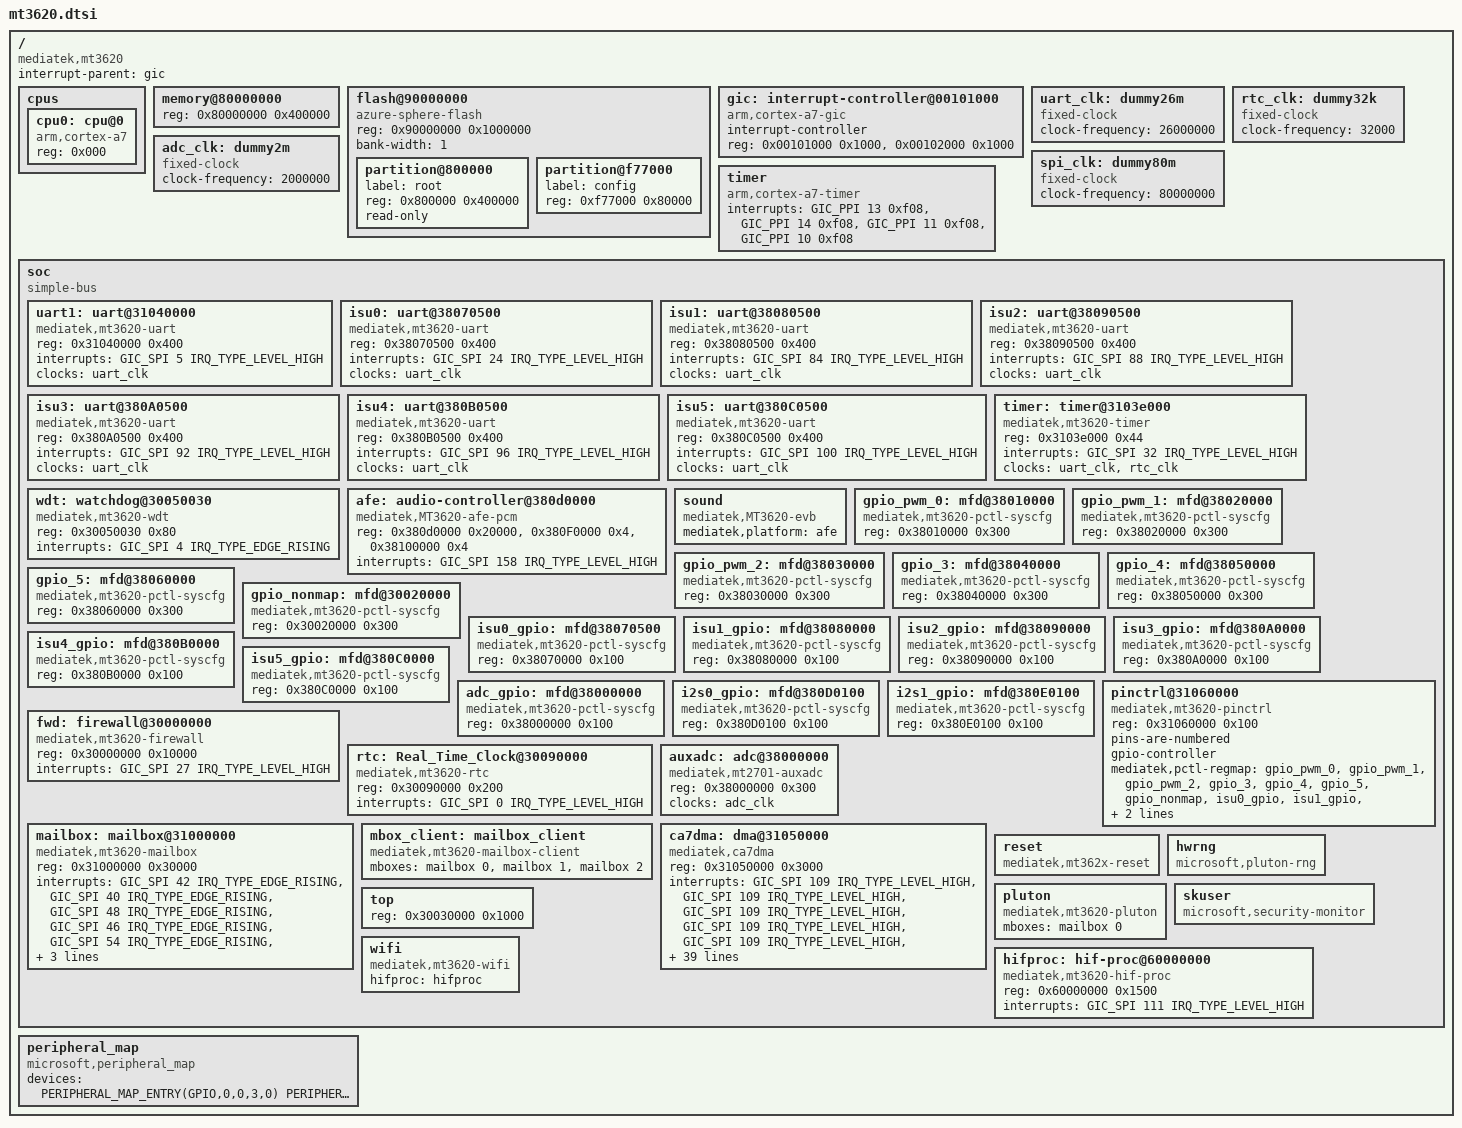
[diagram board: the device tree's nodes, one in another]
// SPDX-License-Identifier: GPL-2.0
/*
 * MT3620 SoC
 *
 * Copyright (c) 2018 Microsoft Corporation. All rights reserved.
 *
 * This program is free software; you can redistribute it and/or modify it
 * under the terms and conditions of the GNU General Public License,
 * version 2, as published by the Free Software Foundation.
 *
 * This program is distributed in the hope it will be useful, but WITHOUT
 * ANY WARRANTY; without even the implied warranty of MERCHANTABILITY or
 * FITNESS FOR A PARTICULAR PURPOSE.  See the GNU General Public License for
 * more details.
 *
 * You should have received a copy of the GNU General Public License along with
 * this program; if not, write to the Free Software Foundation, Inc., 59 Temple
 * Place - Suite 330, Boston, MA 02111-1307 USA.
 *
 */

#include <dt-bindings/interrupt-controller/irq.h>
#include <dt-bindings/interrupt-controller/arm-gic.h>
#include "mt3620-peripherals.dtsi"

/ {
	compatible = "mediatek,mt3620";
	interrupt-parent = <&gic>;

	//
	// We only need one 32-bit value each to represent physical addresses and
	// sizes.  This means that 'reg' values will tend to take the form:
	//
	//     <[addr] [size]>
	//

	#address-cells = <1>;
	#size-cells = <1>;

	//
	// We use 3 values to represent interrupts; from gic.txt:
	//   * 1st cell: 0 for SPI interrupts, 1 for PPI interrupts
	//   * 2nd cell: interrupt number (SPI: [0-987], PPI: [0-15])
	//   * 3rd cell: flags
	//     - bits[3:0]: trigger type / level flags
	//       + 1 = low-to-high edge triggered
	//       + 2 = high-to-low edge triggered (invalid for SPIs)
	//       + 4 = active high level-sensitive
	//       + 8 = active low level-sensitive (invalid for SPIs)
	//     - bits[15:8] PPI interrupt cpu mask; only valid for PPI interrupts
	//

	//
	// Define the CPU.
	//
	// ref: Documentation/devicetree/bindings/arm/cpus.txt
	//

	cpus {
		#address-cells = <1>;
		#size-cells = <0>;

		cpu0: cpu@0 {
			device_type = "cpu";
			compatible = "arm,cortex-a7";

			//
			// Register must match the CPU MPIDR[23:0] register bits.
			//

			reg = <0x000>;
		};
	};

	//
	// Define the A7's SRAMs.

	memory@80000000 {
		device_type = "memory";
		reg = <0x80000000 0x400000>;
	};

	//
	// We define a flash device to cover the XIP mapping of flash into the
	// physical address space.
	//
	// We mark the device as being "mtd-rom" so that it's managed by a read-only
	// MTD device that directly reads from physical memory.
	//
	// ref: Documentation/devicetree/bindings/mtd/mtd-physmap.txt
	//

	flash@90000000 {
		compatible = "azure-sphere-flash", "mtd-rom";
		reg = <0x90000000 0x1000000>;

		//
		// NOTE: We need to specify "bank-width" but it's not clear that
		// it has much meaning here.
		//

		bank-width = <1>;

		//
		// We define the partition structure here; note that this
		// will be overwritten by our NW loader based on the
		// partition table.
		//
		// ref: Documentation/devicetree/bindings/mtd/partition.txt
		//

		partition@800000 {
		    label = "root";
		    reg = <0x800000 0x400000>; /* 8 MiB - 12 MiB */
		    read-only;
		};

		partition@f77000 {
		    label = "config";
		    reg = <0xf77000 0x80000>;
		};
	};

	//
	// We have a GICv2 in our standard MPCore peripherals.
	//
	// ref: Documentation/devicetree/bindings/arm/gic.txt
	//

	gic: interrupt-controller@00101000 {
		compatible = "arm,cortex-a7-gic";
		#interrupt-cells = <3>;
		#address-cells = <0>;
		interrupt-controller;

		//
		// We need to specify the base physical addresses and sizes of the
		// GIC registers:
		//
		//   * Region 0: GIC distributor register base and size
		//   * Region 1: GIC CPU interface register base and size
		//
		// For ARM cores with virtualization extensions, additional registers
		// must be specified:
		//
		//   * Region 2: GIC virtual interface control register base and size
		//   * Region 3: GIC virtual CPU interface register base and size
		//
		// If present, the VGIC maintenance interrupt is specified as an
		// interrupt source here.
		//

		reg = <0x00101000 0x1000>,
		      <0x00102000 0x1000>;
	};

	//
	// The UART clock is based on a fixed, 26 MHz clock source.
	//
	// ref: Documentation/devicetree/bindings/clock/fixed-clock.txt
	//

	uart_clk: dummy26m {
		compatible = "fixed-clock";
		clock-frequency = <26000000>;
		#clock-cells = <0>;
	};

	rtc_clk: dummy32k {
		compatible = "fixed-clock";
		clock-frequency = <32000>;
		#clock-cells = <0>;
	};

	adc_clk: dummy2m {
		compatible = "fixed-clock";
		clock-frequency = <2000000>;
		#clock-cells = <0>;
	};

	// SPIM clock: 
	// selected by rg_spim_clk_div_sel; pluton-runtime
	// programs this this to 80MHz.

	spi_clk: dummy80m {
		compatible = "fixed-clock";
		clock-frequency = <80000000>;
		#clock-cells = <0>;
	};


	//
	// Include the ARM architectural timer.
	//
	// ref: Documentation/devicetree/bindings/arm/arch_timer.txt
	//

	timer {
		compatible = "arm,cortex-a7-timer",
			     "arm,armv7-timer";

		#interrupt-cells = <3>;

		interrupts = <GIC_PPI 13 0xf08>,
			     <GIC_PPI 14 0xf08>,
			     <GIC_PPI 11 0xf08>,
			     <GIC_PPI 10 0xf08>;
	};

	//
	// Define a simple bus that doesn't require a software driver.
	//
	// ref: Documentation/devicetree/bindings/arm/simple-pm-bus.txt
	//

	soc: soc {
		// 32-bit space
		#address-cells = <1>;
		#size-cells = <1>;

		compatible = "simple-bus";

		//
		// Indicate that there's an identify mapping for addresses on this bus.
		//

		ranges;

		//
		// Define the CA7 UARTs
		// They aren't actually ns16550a devices, but are
		// close-ish.
		//
		// ref: Documentation/devicetree/bindings/serial/8250.txt
		//

		// Debug UART

		uart1: uart@31040000 {
			compatible = "mediatek,mt3620-uart";
			reg = <0x31040000 0x400>;
			interrupts = <GIC_SPI 5 IRQ_TYPE_LEVEL_HIGH>;
			clocks = <&uart_clk>;
		};

		// ISUs

		isu0: uart@38070500 {
			compatible = "mediatek,mt3620-uart";
			reg = <0x38070500 0x400>;
			interrupts = <GIC_SPI 24 IRQ_TYPE_LEVEL_HIGH>;
			clocks = <&uart_clk>;
		};

		isu1: uart@38080500 {
			compatible = "mediatek,mt3620-uart";
			reg = <0x38080500 0x400>;
			interrupts = <GIC_SPI 84 IRQ_TYPE_LEVEL_HIGH>;
			clocks = <&uart_clk>;
		};

		isu2: uart@38090500 {
			compatible = "mediatek,mt3620-uart";
			reg = <0x38090500 0x400>;
			interrupts = <GIC_SPI 88 IRQ_TYPE_LEVEL_HIGH>;
			clocks = <&uart_clk>;
		};

		isu3: uart@380A0500 {
			compatible = "mediatek,mt3620-uart";
			reg = <0x380A0500 0x400>;
			interrupts = <GIC_SPI 92 IRQ_TYPE_LEVEL_HIGH>;
			clocks = <&uart_clk>;
		};

		isu4: uart@380B0500 {
			compatible = "mediatek,mt3620-uart";
			reg = <0x380B0500 0x400>;
			interrupts = <GIC_SPI 96 IRQ_TYPE_LEVEL_HIGH>;
			clocks = <&uart_clk>;
		};

		isu5: uart@380C0500 {
			compatible = "mediatek,mt3620-uart";
			reg = <0x380C0500 0x400>;
			interrupts = <GIC_SPI 100 IRQ_TYPE_LEVEL_HIGH>;
			clocks = <&uart_clk>;
		};

		timer: timer@3103e000 {
				compatible = "mediatek,mt3620-timer";
				reg = <0x3103e000 0x44>;
				interrupts = <GIC_SPI 32 IRQ_TYPE_LEVEL_HIGH>;
				clocks = <&uart_clk>, <&rtc_clk>;
				clock-names = "system-clk", "rtc-clk";
		};

		//
		// Define the A7's watchdog timer.
		//

		wdt: watchdog@30050030 {
				compatible = "mediatek,mt3620-wdt";
				reg = <0x30050030 0x80>;
				interrupts = <GIC_SPI 4 IRQ_TYPE_EDGE_RISING>;
		};

		// TODO: various peripherals that MTK defined here...

		afe: audio-controller@380d0000 {
			compatible = "mediatek,MT3620-afe-pcm";
			reg = <0x380d0000 0x20000>,
			      <0x380F0000 0x4>,
			      <0x38100000 0x4>;
			interrupts =<GIC_SPI 158 IRQ_TYPE_LEVEL_HIGH>;  //i2s0:158 i2s1:159
			//status = "disabled";
		};

		sound: sound {
			compatible = "mediatek,MT3620-evb";
			mediatek,platform = <&afe>;
			status = "okay";
		};

		gpio_pwm_0: mfd@38010000 {
			compatible = "mediatek,mt3620-pctl-syscfg", "syscon";
			reg = <0x38010000 0x300>;
		};

		gpio_pwm_1: mfd@38020000 {
			compatible = "mediatek,mt3620-pctl-syscfg", "syscon";
			reg = <0x38020000 0x300>;
		};

		gpio_pwm_2: mfd@38030000 {
			compatible = "mediatek,mt3620-pctl-syscfg", "syscon";
			reg = <0x38030000 0x300>;
		};

		gpio_3: mfd@38040000 {
			compatible = "mediatek,mt3620-pctl-syscfg", "syscon";
			reg = <0x38040000 0x300>;
		};

		gpio_4: mfd@38050000 {
			compatible = "mediatek,mt3620-pctl-syscfg", "syscon";
			reg = <0x38050000 0x300>;
		};

		gpio_5: mfd@38060000 {
			compatible = "mediatek,mt3620-pctl-syscfg", "syscon";
			reg = <0x38060000 0x300>;
		};

		gpio_nonmap: mfd@30020000 {
			compatible = "mediatek,mt3620-pctl-syscfg", "syscon";
			reg = <0x30020000 0x300>;
		};

		isu0_gpio: mfd@38070500 {
			compatible = "mediatek,mt3620-pctl-syscfg", "syscon";
			reg = <0x38070000 0x100>;
		};

		isu1_gpio: mfd@38080000 {
			compatible = "mediatek,mt3620-pctl-syscfg", "syscon";
			reg = <0x38080000 0x100>;
		};

		isu2_gpio: mfd@38090000 {
			compatible = "mediatek,mt3620-pctl-syscfg", "syscon";
			reg = <0x38090000 0x100>;
		};

		isu3_gpio: mfd@380A0000 {
			compatible = "mediatek,mt3620-pctl-syscfg", "syscon";
			reg = <0x380A0000 0x100>;
		};

		isu4_gpio: mfd@380B0000 {
			compatible = "mediatek,mt3620-pctl-syscfg", "syscon";
			reg = <0x380B0000 0x100>;
		};

		isu5_gpio: mfd@380C0000 {
			compatible = "mediatek,mt3620-pctl-syscfg", "syscon";
			reg = <0x380C0000 0x100>;
		};

		adc_gpio: mfd@38000000 {
			compatible = "mediatek,mt3620-pctl-syscfg", "syscon";
			reg = <0x38000000 0x100>;
		};

		i2s0_gpio: mfd@380D0100 {
			compatible = "mediatek,mt3620-pctl-syscfg", "syscon";
			reg = <0x380D0100 0x100>;
		};

		i2s1_gpio: mfd@380E0100 {
			compatible = "mediatek,mt3620-pctl-syscfg", "syscon";
			reg = <0x380E0100 0x100>;
		};

		pinctrl@31060000 {
			compatible = "mediatek,mt3620-pinctrl";
			reg = <0x31060000 0x100>;
			pins-are-numbered;
			gpio-controller;
			#gpio-cells = <2>;
			//  GPIO#  regmap# base     desc                offset
			//  0.. 3     0    38010000 GPIO_PWM_0          0
			//  4.. 7     1    38020000 GPIO_PWM_1          0
			//  8..11     2    38030000 GPIO_PWM_2          0
			// 12..15     3    38040000 GPIO_3              0
			// 16..19     4    38050000 GPIO_4              0
			// 20..23     5    38060000 GPIO_5              0
			// 24..25     6    30020000 ANTSEL0,ANTSEL1     0
			// 26..30     7    38070000 ISU0                0
			// 31..35     8    38080000 ISU1                0
			// 36..40     9    38090000 ISU2                0
			// 41..48    10    38000000 ADC_GPIO            0
			// 49..55     6    30020000 NONMAP              2
			// 56..60    11    380D0100 I2S0_GPIO           0
			// 61..65    12    380E0100 I2S1_GPIO           0
			// 66..70    13    380A0000 ISU3                0
			// 71..75    14    380B0000 ISU4                0
			// 76..80    15    380C0000 ISU5                0
			// 81..93     6    30020000 NONMAP              9..21
			mediatek,pctl-regmap = <&gpio_pwm_0 &gpio_pwm_1
				&gpio_pwm_2 &gpio_3 &gpio_4 &gpio_5 &gpio_nonmap
				&isu0_gpio &isu1_gpio &isu2_gpio  &adc_gpio
				&i2s0_gpio &i2s1_gpio &isu3_gpio &isu4_gpio
				&isu5_gpio>;
		};

		fwd: firewall@30000000 {
			compatible = "mediatek,mt3620-firewall";
			reg = <0x30000000 0x10000>;
			interrupts = <GIC_SPI 27 IRQ_TYPE_LEVEL_HIGH>;
		};

		rtc: Real_Time_Clock@30090000 {
			compatible = "mediatek,mt3620-rtc";
			reg = <0x30090000 0x200>;
			interrupts = <GIC_SPI 0 IRQ_TYPE_LEVEL_HIGH>;
		};

		auxadc: adc@38000000 {
			compatible = "mediatek,mt2701-auxadc";
			reg = <0x38000000 0x300>;
			clocks = <&adc_clk>;
			clock-names = "main";
			#io-channel-cells = <1>;
		};

		//
		// Define our mailboxes used for A7->M4-HSP/IO0/IO1 communication
		//
		//
		// rdIrq is when we have data available (rx)
		// wrIrq is when we have data sent (tx)
		//
		// Note - the ARM GIC interrupt controller adds 32 to the number below - so these are the hardware IRQs - 32.
		//
		mailbox: mailbox@31000000 {
			compatible = "mediatek,mt3620-mailbox";
			reg = <0x31000000 0x30000>;
			#interrupt-cells = <3>;

			interrupts = <GIC_SPI 42 IRQ_TYPE_EDGE_RISING>, // WR
				     <GIC_SPI 40 IRQ_TYPE_EDGE_RISING>,	// RD
				     <GIC_SPI 48 IRQ_TYPE_EDGE_RISING>, // WR
				     <GIC_SPI 46 IRQ_TYPE_EDGE_RISING>,	// RD
				     <GIC_SPI 54 IRQ_TYPE_EDGE_RISING>, // WR
				     <GIC_SPI 52 IRQ_TYPE_EDGE_RISING>;	// RD
			#mbox-cells = <1>;
			mailbox-channel-count = <3>;
			mailbox-max-fifo-count = <15>;
		};

		mbox_client: mailbox_client {
			compatible = "mediatek,mt3620-mailbox-client";
			mboxes = <&mailbox 0>,
				<&mailbox 1>,
				<&mailbox 2>;
		};

		ca7dma: dma@31050000 {
			compatible = "mediatek,ca7dma";
			reg = <0x31050000 0x3000>;
			/* dma channel 0-33 share one irq */
			interrupts = <GIC_SPI 109 IRQ_TYPE_LEVEL_HIGH>,
								<GIC_SPI 109 IRQ_TYPE_LEVEL_HIGH>,
								<GIC_SPI 109 IRQ_TYPE_LEVEL_HIGH>,
								<GIC_SPI 109 IRQ_TYPE_LEVEL_HIGH>,
								<GIC_SPI 109 IRQ_TYPE_LEVEL_HIGH>,
								<GIC_SPI 109 IRQ_TYPE_LEVEL_HIGH>,
								<GIC_SPI 109 IRQ_TYPE_LEVEL_HIGH>,
								<GIC_SPI 109 IRQ_TYPE_LEVEL_HIGH>,
								<GIC_SPI 109 IRQ_TYPE_LEVEL_HIGH>,
								<GIC_SPI 109 IRQ_TYPE_LEVEL_HIGH>,
								<GIC_SPI 109 IRQ_TYPE_LEVEL_HIGH>,
								<GIC_SPI 109 IRQ_TYPE_LEVEL_HIGH>,
								<GIC_SPI 109 IRQ_TYPE_LEVEL_HIGH>,
								<GIC_SPI 109 IRQ_TYPE_LEVEL_HIGH>,
								<GIC_SPI 109 IRQ_TYPE_LEVEL_HIGH>,
								<GIC_SPI 109 IRQ_TYPE_LEVEL_HIGH>,
								<GIC_SPI 109 IRQ_TYPE_LEVEL_HIGH>,
								<GIC_SPI 109 IRQ_TYPE_LEVEL_HIGH>,
								<GIC_SPI 109 IRQ_TYPE_LEVEL_HIGH>,
								<GIC_SPI 109 IRQ_TYPE_LEVEL_HIGH>,
								<GIC_SPI 109 IRQ_TYPE_LEVEL_HIGH>,
								<GIC_SPI 109 IRQ_TYPE_LEVEL_HIGH>,
								<GIC_SPI 109 IRQ_TYPE_LEVEL_HIGH>,
								<GIC_SPI 109 IRQ_TYPE_LEVEL_HIGH>,
								<GIC_SPI 109 IRQ_TYPE_LEVEL_HIGH>,
								<GIC_SPI 109 IRQ_TYPE_LEVEL_HIGH>,
								<GIC_SPI 109 IRQ_TYPE_LEVEL_HIGH>,
								<GIC_SPI 109 IRQ_TYPE_LEVEL_HIGH>,
								<GIC_SPI 109 IRQ_TYPE_LEVEL_HIGH>,
								<GIC_SPI 109 IRQ_TYPE_LEVEL_HIGH>,
								<GIC_SPI 109 IRQ_TYPE_LEVEL_HIGH>,
								<GIC_SPI 109 IRQ_TYPE_LEVEL_HIGH>,
								<GIC_SPI 109 IRQ_TYPE_LEVEL_HIGH>,
								<GIC_SPI 109 IRQ_TYPE_LEVEL_HIGH>;
			interrupt-names = "peri_dma0",  //ISU0-TX
									"peri_dma1",  //ISU0-RX
									"peri_dma2",  //ISU1-TX
									"peri_dma3",  //ISU1-RX
									"peri_dma4",  //ISU2-TX
									"peri_dma5",  //ISU2-RX
									"peri_dma6",  //ISU3-TX
									"peri_dma7",  //ISU3-RX
									"peri_dma8",  //ISU4-TX
									"peri_dma9",  //ISU4-RX
									"peri_dma10", //ISU5-TX
									"peri_dma11", //ISU5-RX
									"wfsys_dma12", //WFSYS
									"m2m_dma13", //M2M
									"m2m_dma14", //M2M
									"vff_dma15", //ISU0-TX
									"vff_dma16", //ISU0-RX
									"vff_dma17", //ISU1-TX
									"vff_dma18", //ISU1-RX
									"vff_dma19", //ISU2-TX
									"vff_dma20", //ISU2-RX
									"vff_dma21", //ISU3-TX
									"vff_dma22", //ISU3-RX
									"vff_dma23", //ISU4-TX
									"vff_dma24", //ISU4-RX
									"vff_dma25", //ISU5-TX
									"vff_dma26", //ISU5-RX
									"i2s_dma27", //I2S0-TX
									"i2s_dma28", //I2S0-RX
									"i2s_dma29", //I2S1-TX
									"i2s_dma30", //I2S1-RX
									"ur_ca7_dma31", //UART_CA7-TX
									"ur_ca7_dma32", //UART_CA7-RX
									"adc_dma33"; //ADC-RX
			#dma-cells = <1>;
			mediatek,ca7dma-dma-num = <34>;
			mediatek,ca7dma-m2m-ch-s = <13>;
			mediatek,ca7dma-m2m-ch-e = <14>;
			mediatek,ca7dma-m2m-ch-num = <2>;
			mediatek,ca7dma-peri-ch-s = <0>;
			mediatek,ca7dma-peri-ch-e = <12>;
			mediatek,ca7dma-peri-ch-num = <13>;
			mediatek,ca7dma-vff-ch-s = <15>;
			mediatek,ca7dma-vff-ch-e = <33>;
			mediatek,ca7dma-vff-ch-num = <19>;
			status = "okay";
		};

		//
		// Define our H/W power reset driver that does reboot and power off
		//
		reset {
			compatible = "mediatek,mt362x-reset";
		};

		//
		// Define our hardware random number generator driver that communicates over the rproc
		//
		// The only required setting here is the rproc parameter, which must reference the rproc device.
		//

		hwrng {
			compatible = "microsoft,pluton-rng";
		};

		//
		// Define our client for Pluton communication
		//
		// The two mailboxes (in order) are the data mailbox for large data transfers
		// and the event mailbox for quick commands
		//
		pluton: pluton {
			compatible = "mediatek,mt3620-pluton";
			mboxes = <&mailbox 0>;
		};

		//
		// Security Monitor API
		//
		skuser {
			compatible = "microsoft,security-monitor";
		};

		top {
			reg = <0x30030000 0x1000>;
		};

		// Define hif proc client for A7->HIF communication

		hifproc: hif-proc@60000000 {
			compatible = "mediatek,mt3620-hif-proc";
			reg = <0x60000000 0x1500>;
			interrupts = <GIC_SPI 111 IRQ_TYPE_LEVEL_HIGH>; // WLAN HIF Interrupt Vector
		};

		//
		// Define our wifi driver that communicates over the hifproc
		//
		// The only required setting here is the hifproc parameter, which must reference the hifproc device.
		//

		wifi {
			compatible = "mediatek,mt3620-wifi";
			hifproc = <&hifproc>;
		};
	};

	//
	// the first 32-bit matches the in-memory representation of PeripheralPinSpecifier
	// the second 32-bit uses 16-bit for a pin mask and a 16-bit logical
	// pin number.
	//
	// For example, PERIPHERAL_MAP_ENTRY(UART,4,UART_RX,UART_RTS,26)
	// defines UART4, Pin RX..RTS to start at pin 26. In detail:
	//
	// Pin 26: UART4 "RX"
	// Pin 27: UART4 "TX"
	// Pin 28: UART4 "CTS"
	// Pin 29: UART4 "RTS"
	//

	peripheral_map {
		compatible = "microsoft,peripheral_map";
		devices = <
		                // GPIO0,PWM0
		           PERIPHERAL_MAP_ENTRY(GPIO,0,0,3,0)
		           PERIPHERAL_MAP_ENTRY(PWM,0,0,3,0)
		           PERIPHERAL_MAP_ENTRY(EINT,0,0,7,0)
		                // GPIO1,PWM1
		           PERIPHERAL_MAP_ENTRY(GPIO,1,0,3,4)
		           PERIPHERAL_MAP_ENTRY(PWM,1,0,3,4)
		                // GPIO2,PWM2
		           PERIPHERAL_MAP_ENTRY(GPIO,2,0,3,8)
		           PERIPHERAL_MAP_ENTRY(PWM,2,0,3,8)
		           PERIPHERAL_MAP_ENTRY(EINT,0,8,15,8)
		                // GPIO3
		           PERIPHERAL_MAP_ENTRY(GPIO,3,0,3,12)
		                // GPIO4
		           PERIPHERAL_MAP_ENTRY(GPIO,4,0,3,16)
		           PERIPHERAL_MAP_ENTRY(EINT,0,16,23,16)
		                // GPIO5
		           PERIPHERAL_MAP_ENTRY(GPIO,5,0,3,20)
		                // ISU0: GPIO6,UART4,SPI0,I2C0
		           PERIPHERAL_MAP_ENTRY(GPIO,6,0,5,26)
		           PERIPHERAL_MAP_ENTRY(UART,4,UART_TX,UART_TX,26)
		           PERIPHERAL_MAP_ENTRY(UART,4,UART_RTS,UART_RTS,27)
		           PERIPHERAL_MAP_ENTRY(UART,4,UART_RX,UART_RX,28)
		           PERIPHERAL_MAP_ENTRY(UART,4,UART_CTS,UART_CTS,29)
		           PERIPHERAL_MAP_ENTRY(SPI_MASTER,0,SPI_MOSI,SPI_CS_B,26)
		           PERIPHERAL_MAP_ENTRY(I2C,0,I2C_SCL,I2C_SDA,26)
		                // ISU1: GPIO7,UART5,SPI1,I2C1
		           PERIPHERAL_MAP_ENTRY(GPIO,7,0,5,31)
		           PERIPHERAL_MAP_ENTRY(UART,5,UART_TX,UART_TX,31)
		           PERIPHERAL_MAP_ENTRY(UART,5,UART_RTS,UART_RTS,32)
		           PERIPHERAL_MAP_ENTRY(UART,5,UART_RX,UART_RX,33)
		           PERIPHERAL_MAP_ENTRY(UART,5,UART_CTS,UART_CTS,34)
		           PERIPHERAL_MAP_ENTRY(SPI_MASTER,1,SPI_MOSI,SPI_CS_B,31)
		           PERIPHERAL_MAP_ENTRY(I2C,1,I2C_SCL,I2C_SDA,31)
		                // ISU2: GPIO8,UART6,SPI2,I2C2
		           PERIPHERAL_MAP_ENTRY(GPIO,8,0,5,36)
		           PERIPHERAL_MAP_ENTRY(UART,6,UART_TX,UART_TX,36)
		           PERIPHERAL_MAP_ENTRY(UART,6,UART_RTS,UART_RTS,37)
		           PERIPHERAL_MAP_ENTRY(UART,6,UART_RX,UART_RX,38)
		           PERIPHERAL_MAP_ENTRY(UART,6,UART_CTS,UART_CTS,39)
		           PERIPHERAL_MAP_ENTRY(SPI_MASTER,2,SPI_MOSI,SPI_CS_B,36)
		           PERIPHERAL_MAP_ENTRY(I2C,2,I2C_SCL,I2C_SDA,36)
		                // ADC: GPIO12
		           PERIPHERAL_MAP_ENTRY(GPIO,12,0,7,41)
		                // I2S0,1: GPIO13,14
		           PERIPHERAL_MAP_ENTRY(GPIO,13,0,5,56)
		           PERIPHERAL_MAP_ENTRY(GPIO,14,0,5,61)
		                // ISU3: GPIO9,UART7,SPI3,I2C3
		           PERIPHERAL_MAP_ENTRY(GPIO,9,0,5,66)
		           PERIPHERAL_MAP_ENTRY(UART,7,UART_TX,UART_TX,66)
		           PERIPHERAL_MAP_ENTRY(UART,7,UART_RTS,UART_RTS,67)
		           PERIPHERAL_MAP_ENTRY(UART,7,UART_RX,UART_RX,68)
		           PERIPHERAL_MAP_ENTRY(UART,7,UART_CTS,UART_CTS,69)
		           PERIPHERAL_MAP_ENTRY(SPI_MASTER,3,SPI_MOSI,SPI_CS_B,66)
		           PERIPHERAL_MAP_ENTRY(I2C,3,I2C_SCL,I2C_SDA,66)
		                // ISU4: GPIO10,UART8,SPI4,I2C4
		           PERIPHERAL_MAP_ENTRY(GPIO,10,0,5,71)
		           PERIPHERAL_MAP_ENTRY(UART,8,UART_TX,UART_TX,71)
		           PERIPHERAL_MAP_ENTRY(UART,8,UART_RTS,UART_RTS,72)
		           PERIPHERAL_MAP_ENTRY(UART,8,UART_RX,UART_RX,73)
		           PERIPHERAL_MAP_ENTRY(UART,8,UART_CTS,UART_CTS,74)
		           PERIPHERAL_MAP_ENTRY(SPI_MASTER,4,SPI_MOSI,SPI_CS_B,71)
		           PERIPHERAL_MAP_ENTRY(I2C,4,I2C_SCL,I2C_SDA,71)
		                // ISU5: GPIO11,UART9,SPI5,I2C5
		           PERIPHERAL_MAP_ENTRY(GPIO,11,0,5,76)
		           PERIPHERAL_MAP_ENTRY(UART,9,UART_TX,UART_TX,76)
		           PERIPHERAL_MAP_ENTRY(UART,9,UART_RTS,UART_RTS,77)
		           PERIPHERAL_MAP_ENTRY(UART,9,UART_RX,UART_RX,78)
		           PERIPHERAL_MAP_ENTRY(UART,9,UART_CTS,UART_CTS,79)
		           PERIPHERAL_MAP_ENTRY(SPI_MASTER,5,SPI_MOSI,SPI_CS_B,76)
		           PERIPHERAL_MAP_ENTRY(I2C,5,I2C_SCL,I2C_SDA,76)

		                // A7 UART: UART1
		           // No entry here for UART1 - because it is shared
		           // with security monitor, we can not allow kernel
		           // to re-mux to something other than UART.
		           // The entry would be:
		           // PERIPHERAL_MAP_ENTRY(UART,1,UART_RX,UART_RTS,49)
		>;
	};

};
